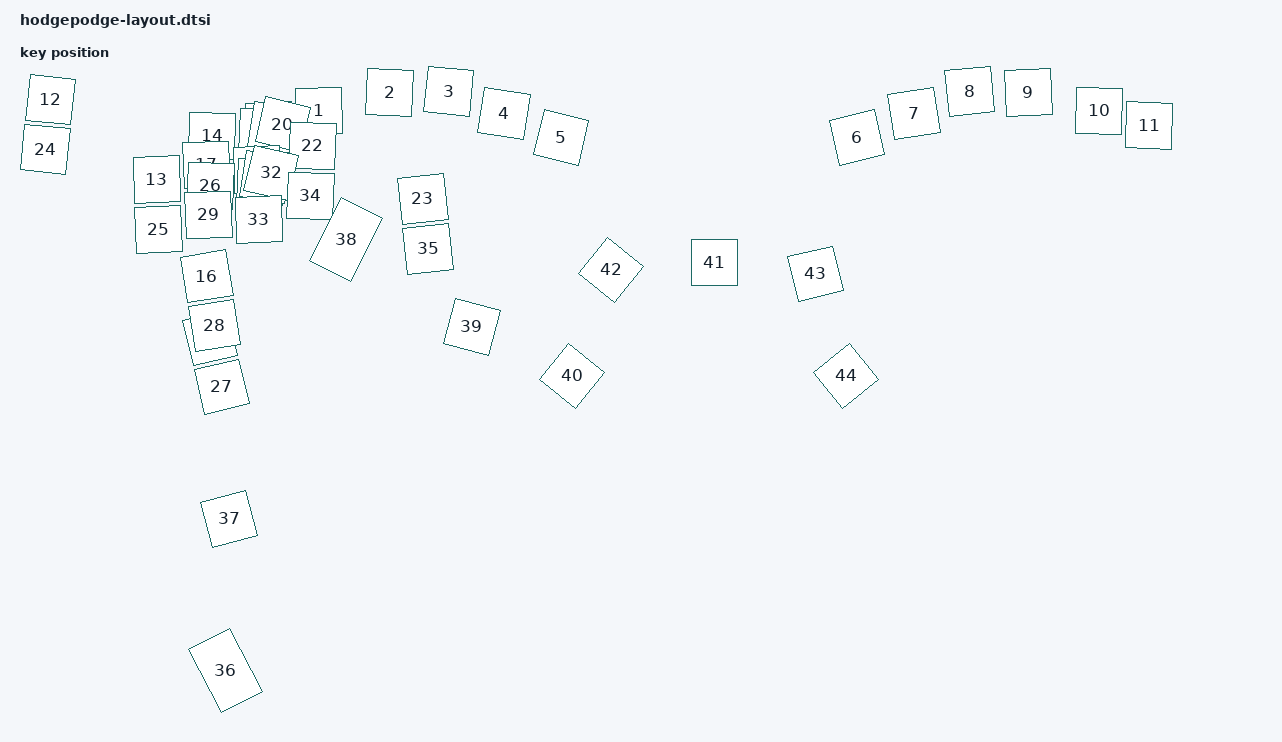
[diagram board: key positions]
#include <physical_layouts.dtsi>

/ {
	hodgepodge_physical_layout: hodgepodge_physical_layout {
		compatible = "zmk,physical-layout";
		display-name = "HodgePodge Layout";
		keys
		=             <&key_physical_attrs 100 100  493   59 (-200)  693  359>
		,             <&key_physical_attrs 100 100  593   34 (-200)  693  334>
		,             <&key_physical_attrs 100 100  717    0    200  817  300>
		,             <&key_physical_attrs 100 100  790   37    600 1255  577>
		,             <&key_physical_attrs 100 100  916   30    900  916  330>
		,             <&key_physical_attrs 100 100 1014   71   1300 1014  371>
		,             <&key_physical_attrs 100 100 1715   71 (-1300) 1815  371>
		,             <&key_physical_attrs 100 100 1813   30 (-900) 1913  330>
		,             <&key_physical_attrs 100 100 1939   37 (-600) 1574  577>
		,             <&key_physical_attrs 100 100 2012    0 (-200) 2012  300>
		,             <&key_physical_attrs 100 100 2136   34    200 2136  334>
		,             <&key_physical_attrs 100 100 2236   59    200 2136  359>
		,             <&key_physical_attrs 100 100    0  137    600 1255  577>
		,             <&key_physical_attrs 100 100  265  159 (-200)  693  359>
		,             <&key_physical_attrs 100 100  365  100    200  817  300>
		,             <&key_physical_attrs 100 100  365  171 (-1300) 1815  371>
		,             <&key_physical_attrs 100 100  365  130 (-900) 1913  330>
		,             <&key_physical_attrs 100 100  365  134 (-200)  693  334>
		,             <&key_physical_attrs 100 100  465  134    200 2136  334>
		,             <&key_physical_attrs 100 100  465  130    900  916  330>
		,             <&key_physical_attrs 100 100  465  171   1300 1014  371>
		,             <&key_physical_attrs 100 100  465  100 (-200) 2012  300>
		,             <&key_physical_attrs 100 100  565  159    200 2136  359>
		,             <&key_physical_attrs 100 100  829  137 (-600) 1574  577>
		,             <&key_physical_attrs 100 100    0  237    600 1255  577>
		,             <&key_physical_attrs 100 100  265  259 (-200)  693  359>
		,             <&key_physical_attrs 100 100  365  200    200  817  300>
		,             <&key_physical_attrs 100 100  365  271 (-1300) 1815  371>
		,             <&key_physical_attrs 100 100  365  230 (-900) 1913  330>
		,             <&key_physical_attrs 100 100  365  234 (-200)  693  334>
		,             <&key_physical_attrs 100 100  465  234    200 2136  334>
		,             <&key_physical_attrs 100 100  465  230    900  916  330>
		,             <&key_physical_attrs 100 100  465  271   1300 1014  371>
		,             <&key_physical_attrs 100 100  465  200 (-200) 2012  300>
		,             <&key_physical_attrs 100 100  565  259    200 2136  359>
		,             <&key_physical_attrs 100 100  829  237 (-600) 1574  577>
		,             <&key_physical_attrs 100 150  265  377 (-2700) 1950  553>
		,             <&key_physical_attrs 100 100  365  453 (-1500) 1950  553>
		,             <&key_physical_attrs 100 150  564  377   2700  879  553>
		,             <&key_physical_attrs 100 100  879  453   1500  879  553>
		,             <&key_physical_attrs 100 100 1072  387   3900  879  553>
		,             <&key_physical_attrs 100 100 1375  339      0 1425  389>
		,             <&key_physical_attrs 100 100 1172  112   3900  879  278>
		,             <&key_physical_attrs 100 100 1590  371 (-1300) 1590  471>
		,             <&key_physical_attrs 100 100 1658  387 (-3900) 1950  553>
		;
	};
};
